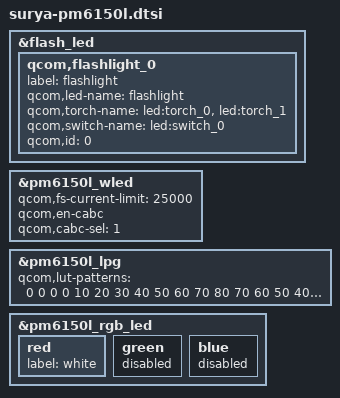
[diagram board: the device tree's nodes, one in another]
&flash_led {
	qcom,flashlight_0 {
		label = "flashlight";
		qcom,led-name = "flashlight";
		qcom,torch-name = "led:torch_0", "led:torch_1";
		qcom,switch-name = "led:switch_0";
		qcom,id = <0>;
	};
};

&pm6150l_wled {
	qcom,fs-current-limit = <25000>;
	qcom,en-cabc;
	qcom,cabc-sel = <1>;
	status = "ok";
};

&pm6150l_lpg {
	qcom,lut-patterns = <0 0 0 0 10 20 30 40 50 60 70 80 70
				60 50 40 30 20 10 0 0 0 0>;
};

&pm6150l_rgb_led {
	red {
		label = "white";
	};

	green {
		status = "disabled";
	};

	blue {
		status = "disabled";
	};
};
